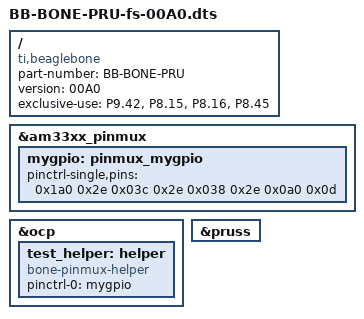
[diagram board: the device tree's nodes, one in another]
/*
* pru dts file BB-BONE-PRU-fs-00A0.dts
*/

/dts-v1/;
/plugin/;

/ {
  compatible = "ti,beaglebone", "ti,beaglebone-black";

  /* identification */
  part-number = "BB-BONE-PRU";
  version = "00A0";
  exclusive-use =
    "P9.42", /* GPIO3_18 pr1_pru0_pru_r31_4 */
    "P8.15", /* GPIO1_15 pr1_pru0_pru_r31_15 */
    "P8.16", /* GPIO1_14 pr1_pru0_pru_r31_14 */
    "P8.45"; /* GPIO2_6  pr1_pru1_pru_r30_0 */

  fragment@0 {
    target = <&am33xx_pinmux>;
    __overlay__ {

      mygpio: pinmux_mygpio{
        pinctrl-single,pins = <
		0x1a0 0x2e 0x03c 0x2e 0x038 0x2e 0x0a0 0x0d>;
      };
    };
  };

 

  fragment@1 {

    target = <&ocp>;

    __overlay__ {

      test_helper: helper {

        compatible = "bone-pinmux-helper";

        pinctrl-names = "default";

        pinctrl-0 = <&mygpio>;

        status = "okay";

      };

    };

  };

 

  fragment@2{

  target = <&pruss>;

    __overlay__ {

      status = "okay";

    };

  };

};


